# XHSC_HC32L12X register map
Vendor: XHSC Co.Ltd; Series: ARMCM0P; File version: 1.0
CPU: CM0P r0p0, little endian, no MPU, no FPU, 3 interrupt priority bits
Registers are 32-bit, read-write, reset 0x0 unless marked. A register's access mark holds for its fields unless they carry their own. Offsets are from the block's base; [hi:lo] are bit positions; {n}, {i} and the like mark numbered series.

## GPIO
Base 0x40020C00
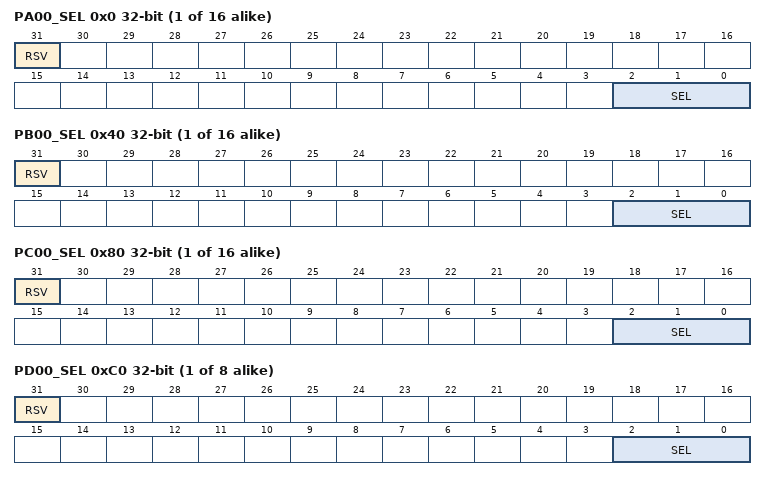
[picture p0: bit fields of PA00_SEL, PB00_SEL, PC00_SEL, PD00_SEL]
{0x0+4i} PA{i:02}_SEL (reset mask 0x7) (i=0..15)
  [31] RSV, [2:0] SEL
{0x40+4i} PB{i:02}_SEL (reset mask 0x7) (i=0..15)
  [31] RSV, [2:0] SEL
{0x80+4i} PC{i:02}_SEL (reset mask 0x7) (i=0..15)
  [31] RSV, [2:0] SEL
{0xC0+4i} PD{i:02}_SEL (reset mask 0x7) (i=0..7)
  [31] RSV, [2:0] SEL
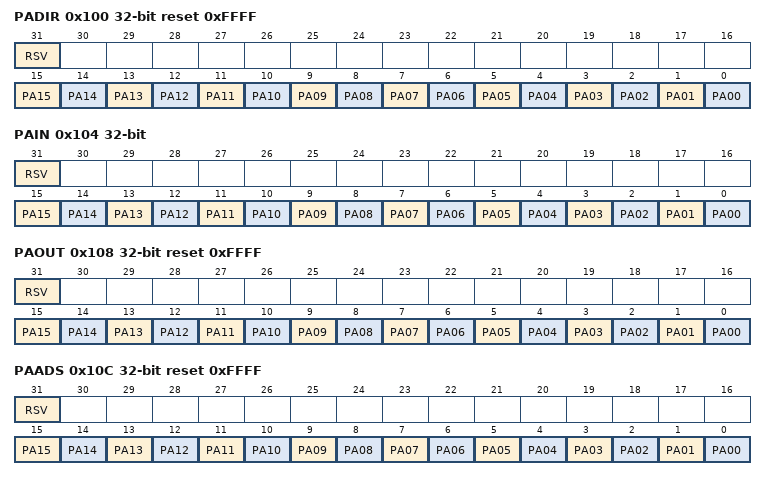
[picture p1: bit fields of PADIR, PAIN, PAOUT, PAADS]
0x100 PADIR reset 0xFFFF (reset mask 0xFFFF)
  [31] RSV, [n] PA{n:02} (n=0..15)
0x104 PAIN ro (reset mask 0xFFFF)
  [31] RSV, [n] PA{n:02} (n=0..15)
0x108 PAOUT reset 0xFFFF (reset mask 0xFFFF)
  [31] RSV, [n] PA{n:02} (n=0..15)
0x10C PAADS reset 0xFFFF (reset mask 0xFFFF)
  [31] RSV, [n] PA{n:02} (n=0..15)
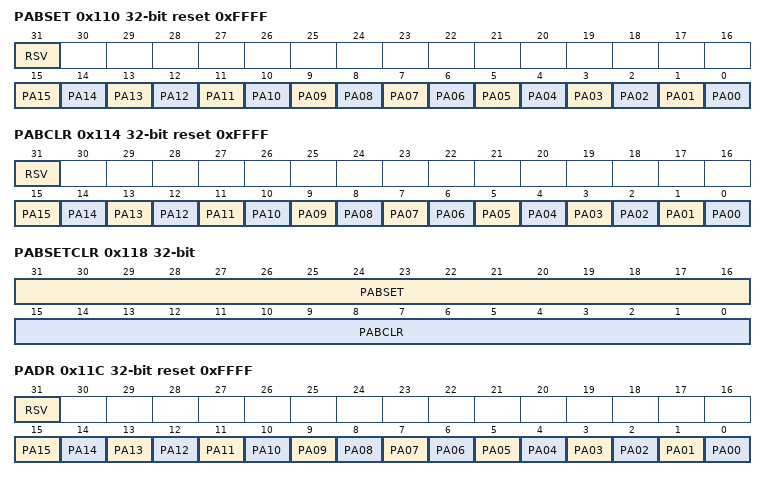
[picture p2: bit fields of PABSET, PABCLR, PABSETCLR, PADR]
0x110 PABSET reset 0xFFFF (reset mask 0xFFFF)
  [31] RSV, [n] PA{n:02} (n=0..15)
0x114 PABCLR reset 0xFFFF (reset mask 0xFFFF)
  [31] RSV, [n] PA{n:02} (n=0..15)
0x118 PABSETCLR
  [31:16] PABSET, [15:0] PABCLR
0x11C PADR reset 0xFFFF (reset mask 0xFFFF)
  [31] RSV, [n] PA{n:02} (n=0..15)
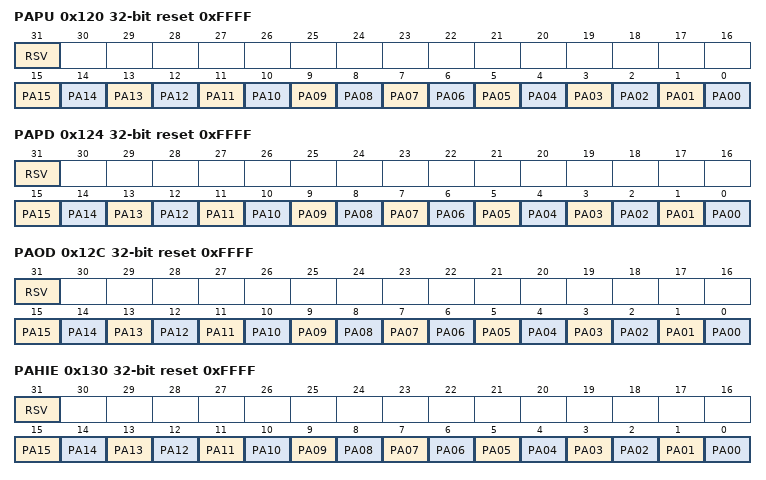
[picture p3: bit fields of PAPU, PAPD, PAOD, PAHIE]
0x120 PAPU reset 0xFFFF (reset mask 0xFFFF)
  [31] RSV, [n] PA{n:02} (n=0..15)
0x124 PAPD reset 0xFFFF (reset mask 0xFFFF)
  [31] RSV, [n] PA{n:02} (n=0..15)
0x12C PAOD reset 0xFFFF (reset mask 0xFFFF)
  [31] RSV, [n] PA{n:02} (n=0..15)
0x130 PAHIE reset 0xFFFF (reset mask 0xFFFF)
  [31] RSV, [n] PA{n:02} (n=0..15)
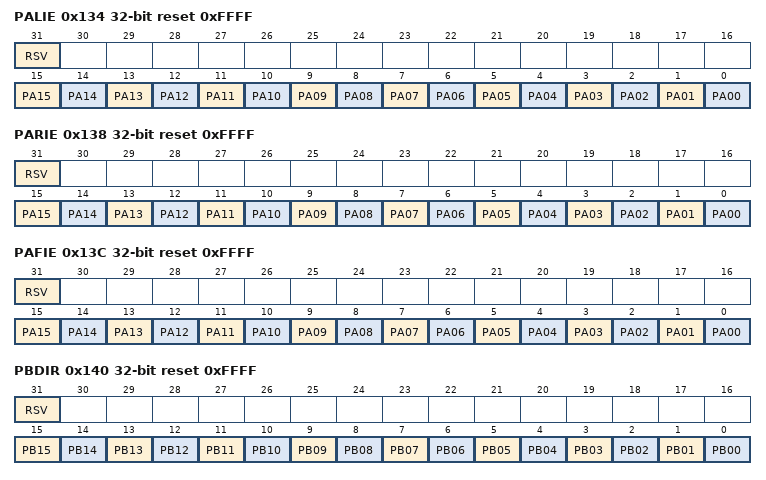
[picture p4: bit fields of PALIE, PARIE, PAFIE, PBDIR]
0x134 PALIE reset 0xFFFF (reset mask 0xFFFF)
  [31] RSV, [n] PA{n:02} (n=0..15)
0x138 PARIE reset 0xFFFF (reset mask 0xFFFF)
  [31] RSV, [n] PA{n:02} (n=0..15)
0x13C PAFIE reset 0xFFFF (reset mask 0xFFFF)
  [31] RSV, [n] PA{n:02} (n=0..15)
0x140 PBDIR reset 0xFFFF (reset mask 0xFFFF)
  [31] RSV, [n] PB{n:02} (n=0..15)
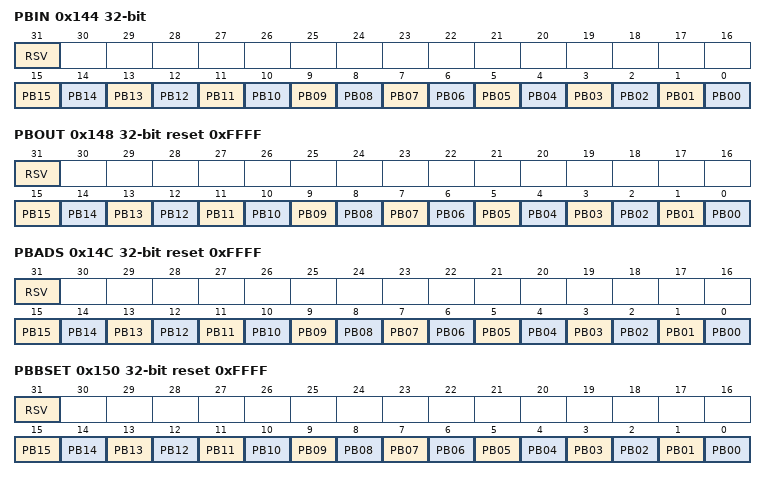
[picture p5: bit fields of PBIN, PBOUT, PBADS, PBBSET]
0x144 PBIN ro (reset mask 0xFFFF)
  [31] RSV, [n] PB{n:02} (n=0..15)
0x148 PBOUT reset 0xFFFF (reset mask 0xFFFF)
  [31] RSV, [n] PB{n:02} (n=0..15)
0x14C PBADS reset 0xFFFF (reset mask 0xFFFF)
  [31] RSV, [n] PB{n:02} (n=0..15)
0x150 PBBSET reset 0xFFFF (reset mask 0xFFFF)
  [31] RSV, [n] PB{n:02} (n=0..15)
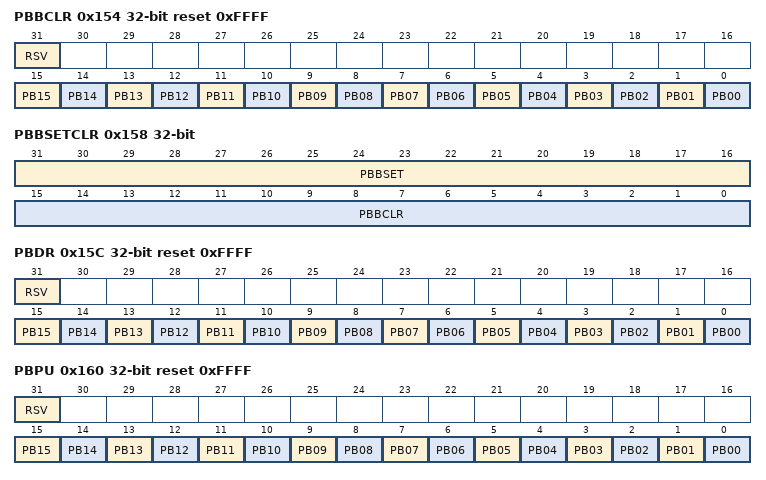
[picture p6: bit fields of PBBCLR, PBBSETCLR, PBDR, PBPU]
0x154 PBBCLR reset 0xFFFF (reset mask 0xFFFF)
  [31] RSV, [n] PB{n:02} (n=0..15)
0x158 PBBSETCLR
  [31:16] PBBSET, [15:0] PBBCLR
0x15C PBDR reset 0xFFFF (reset mask 0xFFFF)
  [31] RSV, [n] PB{n:02} (n=0..15)
0x160 PBPU reset 0xFFFF (reset mask 0xFFFF)
  [31] RSV, [n] PB{n:02} (n=0..15)
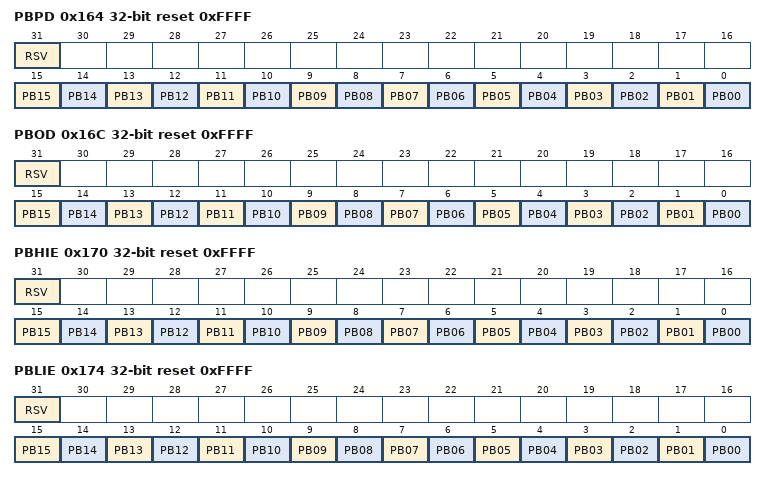
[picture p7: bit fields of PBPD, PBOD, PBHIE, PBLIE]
0x164 PBPD reset 0xFFFF (reset mask 0xFFFF)
  [31] RSV, [n] PB{n:02} (n=0..15)
0x16C PBOD reset 0xFFFF (reset mask 0xFFFF)
  [31] RSV, [n] PB{n:02} (n=0..15)
0x170 PBHIE reset 0xFFFF (reset mask 0xFFFF)
  [31] RSV, [n] PB{n:02} (n=0..15)
0x174 PBLIE reset 0xFFFF (reset mask 0xFFFF)
  [31] RSV, [n] PB{n:02} (n=0..15)
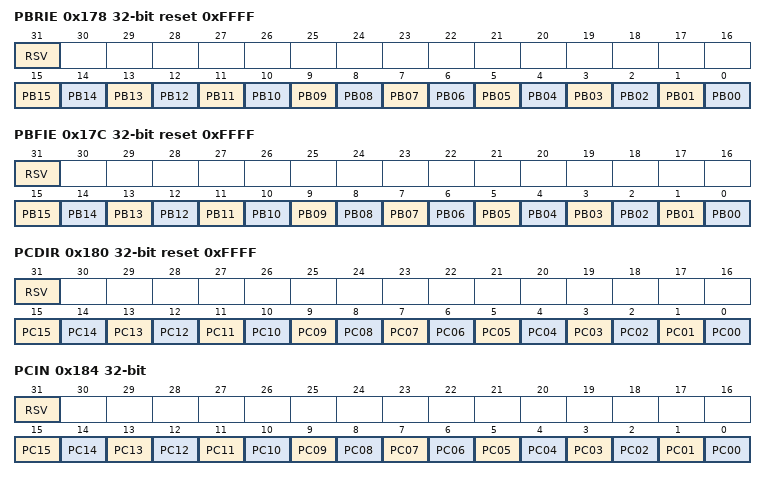
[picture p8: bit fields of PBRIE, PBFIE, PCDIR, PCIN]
0x178 PBRIE reset 0xFFFF (reset mask 0xFFFF)
  [31] RSV, [n] PB{n:02} (n=0..15)
0x17C PBFIE reset 0xFFFF (reset mask 0xFFFF)
  [31] RSV, [n] PB{n:02} (n=0..15)
0x180 PCDIR reset 0xFFFF (reset mask 0xFFFF)
  [31] RSV, [n] PC{n:02} (n=0..15)
0x184 PCIN ro (reset mask 0xFFFF)
  [31] RSV, [n] PC{n:02} (n=0..15)
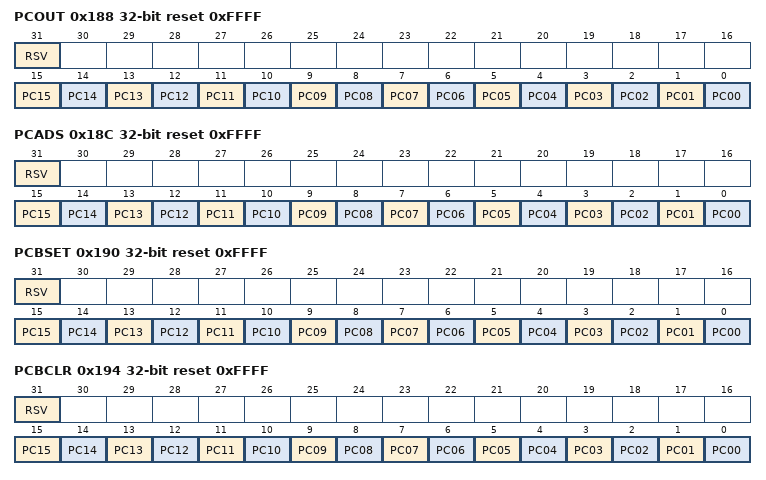
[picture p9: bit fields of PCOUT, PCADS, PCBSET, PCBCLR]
0x188 PCOUT reset 0xFFFF (reset mask 0xFFFF)
  [31] RSV, [n] PC{n:02} (n=0..15)
0x18C PCADS reset 0xFFFF (reset mask 0xFFFF)
  [31] RSV, [n] PC{n:02} (n=0..15)
0x190 PCBSET reset 0xFFFF (reset mask 0xFFFF)
  [31] RSV, [n] PC{n:02} (n=0..15)
0x194 PCBCLR reset 0xFFFF (reset mask 0xFFFF)
  [31] RSV, [n] PC{n:02} (n=0..15)
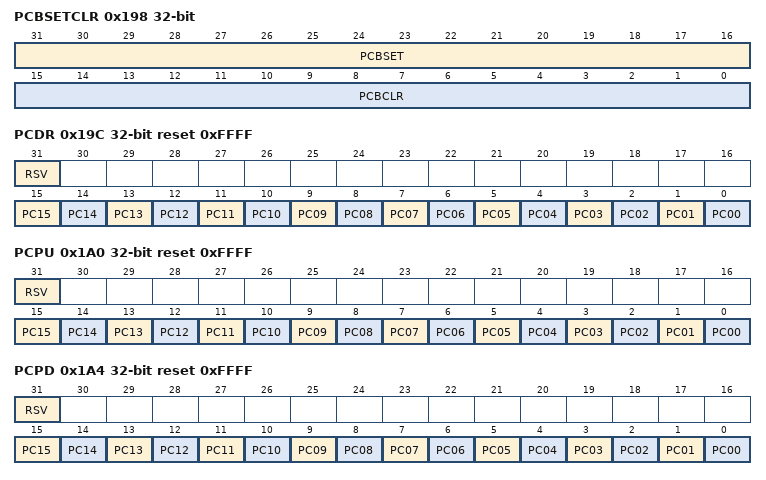
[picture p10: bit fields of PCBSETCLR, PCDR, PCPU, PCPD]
0x198 PCBSETCLR
  [31:16] PCBSET, [15:0] PCBCLR
0x19C PCDR reset 0xFFFF (reset mask 0xFFFF)
  [31] RSV, [n] PC{n:02} (n=0..15)
0x1A0 PCPU reset 0xFFFF (reset mask 0xFFFF)
  [31] RSV, [n] PC{n:02} (n=0..15)
0x1A4 PCPD reset 0xFFFF (reset mask 0xFFFF)
  [31] RSV, [n] PC{n:02} (n=0..15)
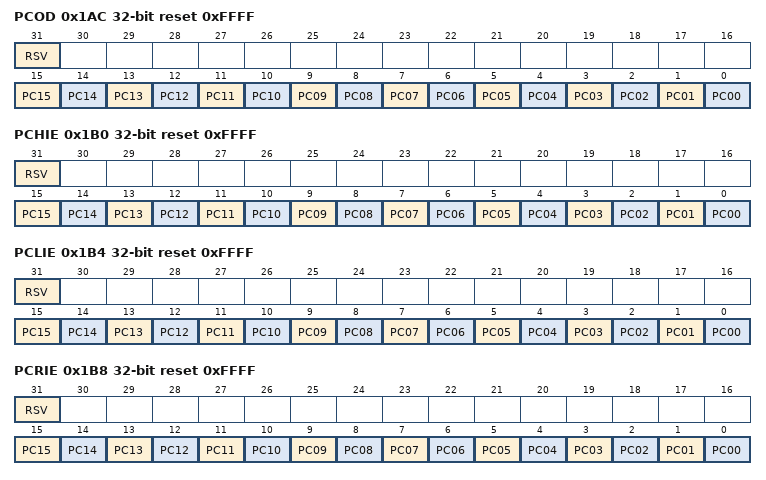
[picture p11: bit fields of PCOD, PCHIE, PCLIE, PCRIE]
0x1AC PCOD reset 0xFFFF (reset mask 0xFFFF)
  [31] RSV, [n] PC{n:02} (n=0..15)
0x1B0 PCHIE reset 0xFFFF (reset mask 0xFFFF)
  [31] RSV, [n] PC{n:02} (n=0..15)
0x1B4 PCLIE reset 0xFFFF (reset mask 0xFFFF)
  [31] RSV, [n] PC{n:02} (n=0..15)
0x1B8 PCRIE reset 0xFFFF (reset mask 0xFFFF)
  [31] RSV, [n] PC{n:02} (n=0..15)
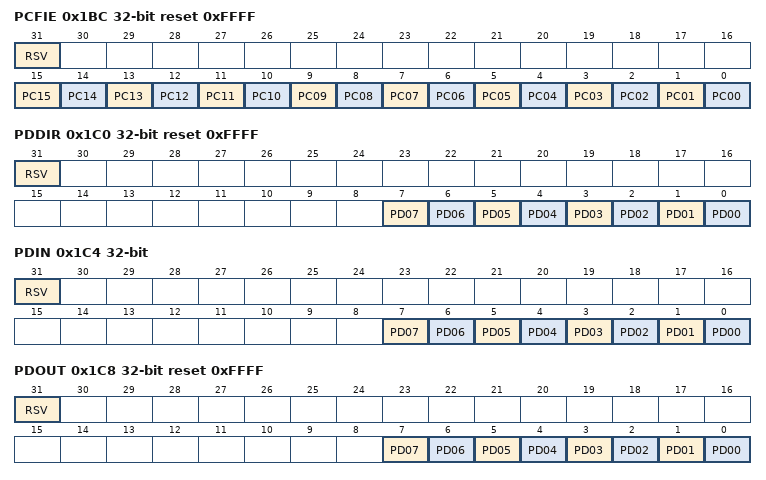
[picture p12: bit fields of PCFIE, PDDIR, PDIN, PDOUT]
0x1BC PCFIE reset 0xFFFF (reset mask 0xFFFF)
  [31] RSV, [n] PC{n:02} (n=0..15)
0x1C0 PDDIR reset 0xFFFF (reset mask 0xF1F)
  [31] RSV, [n] PD{n:02} (n=0..7)
0x1C4 PDIN ro (reset mask 0xF1F)
  [31] RSV, [n] PD{n:02} rw (n=4..7), [n] PD{n:02} (n=0..3)
0x1C8 PDOUT reset 0xFFFF (reset mask 0xF1F)
  [31] RSV, [n] PD{n:02} (n=0..7)
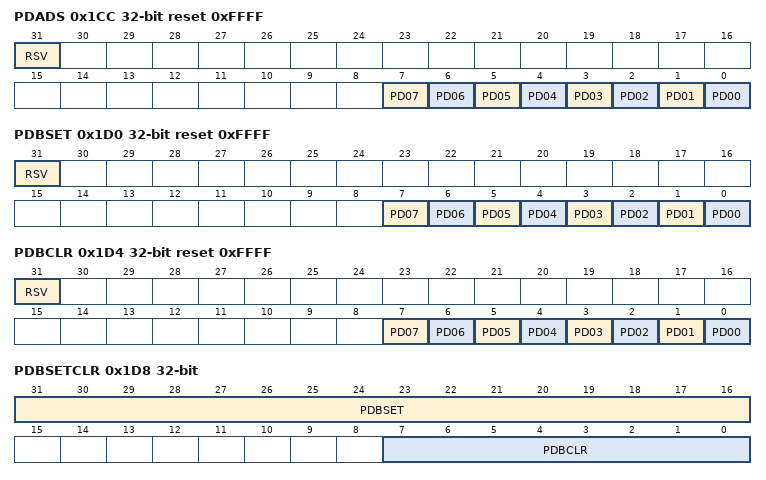
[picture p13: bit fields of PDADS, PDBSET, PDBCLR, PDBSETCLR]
0x1CC PDADS reset 0xFFFF (reset mask 0xF1F)
  [31] RSV, [n] PD{n:02} (n=0..7)
0x1D0 PDBSET reset 0xFFFF (reset mask 0xF1F)
  [31] RSV, [n] PD{n:02} (n=0..7)
0x1D4 PDBCLR reset 0xFFFF (reset mask 0xF1F)
  [31] RSV, [n] PD{n:02} (n=0..7)
0x1D8 PDBSETCLR
  [31:16] PDBSET, [7:0] PDBCLR
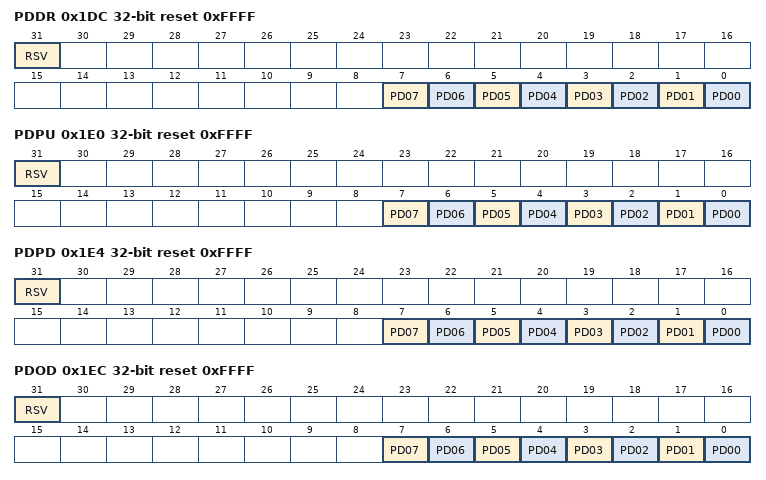
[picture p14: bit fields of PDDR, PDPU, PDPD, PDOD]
0x1DC PDDR reset 0xFFFF (reset mask 0xF1F)
  [31] RSV, [n] PD{n:02} (n=0..7)
0x1E0 PDPU reset 0xFFFF (reset mask 0xF1F)
  [31] RSV, [n] PD{n:02} (n=0..7)
0x1E4 PDPD reset 0xFFFF (reset mask 0xF1F)
  [31] RSV, [n] PD{n:02} (n=0..7)
0x1EC PDOD reset 0xFFFF (reset mask 0xF1F)
  [31] RSV, [n] PD{n:02} (n=0..7)
0x1F0 PDHIE reset 0xFFFF (reset mask 0xF1F)
  [31] RSV, [n] PD{n:02} (n=0..7)
0x1F4 PDLIE reset 0xFFFF (reset mask 0xF1F)
  [31] RSV, [n] PD{n:02} (n=0..7)
0x1F8 PDRIE reset 0xFFFF (reset mask 0xF1F)
  [31] RSV, [n] PD{n:02} (n=0..7)
0x1FC PDFIE reset 0xFFFF (reset mask 0xF1F)
  [31] RSV, [n] PD{n:02} (n=0..7)
0x200 PA_STAT ro (reset mask 0xFFFF)
  [31] RSV, [n] PA{n:02} (n=0..15)
0x210 PA_ICLR reset 0xFFFF (reset mask 0xFFFF)
  [31] RSV, [n] PA{n:02} (n=0..15)
0x240 PB_STAT ro (reset mask 0xFFFF)
  [31] RSV, [n] PB{n:02} (n=0..15)
0x250 PB_ICLR reset 0xFFFF (reset mask 0xFFFF)
  [31] RSV, [n] PB{n:02} (n=0..15)
0x280 PC_STAT ro (reset mask 0xFFFF)
  [31] RSV, [n] PC{n:02} (n=0..15)
0x290 PC_ICLR reset 0xFFFF (reset mask 0xFFFF)
  [31] RSV, [n] PC{n:02} (n=0..15)
0x2C0 PD_STAT ro (reset mask 0xF1F)
  [31] RSV, [n] PD{n:02} rw (n=4..7), [n] PD{n:02} (n=0..3)
0x2D0 PD_ICLR reset 0xFFFF (reset mask 0xF1F)
  [31] RSV, [n] PD{n:02} (n=0..7)
0x304 CTRL1 (reset mask 0x7FFF)
  [31] RSV, [15] HSI2C_LSEL, [14] IR_POL, [13] HCLK_EN, [12] PCLK_EN, [11:10] HCLK_SEL, [9:8] PCLK_SEL
0x308 CTRL2 (reset mask 0x80FF)
  [31] RSV, [15] AHB_SEL, [7:6] TCLK_DIV, [5:4] TCLK_SEL
0x30C TIMGS (reset mask 0x7FFF)
  [31] RSV, [14:12] LPTIM0_G, [3n+2:3n] TIM{n}_G (n=0..3)
0x310 TIMES (reset mask 0x7FFF)
  [31] RSV, [14:12] LPTIM0_E, [3n+2:3n] TIM{n}_E (n=0..3)
0x314 TIMCPS0 (reset mask 0x7FFF)
  [31] RSV, [14:12] TIM3_CB, [3n+2:3n] TIM{n}_CA (n=0..3)
0x318 TIMCPS1 (reset mask 0xFFF)
  [31] RSV, [11:9] LPTIM1_E, [8:6] LPTIM1_G
0x330 FLTCFG (reset mask 0xF)
  [31] RSV, [10] FCLK_SEL, [9:8] FCLK_DIV, [7] PA00FLTEN, [6] PA08FLTEN, [5] PB00FLTEN, [4] PB08FLTEN
